# STM32N645 register map
File version: 1.0
CPU: CM55 r0p1, little endian, no MPU, FPU, vendor SysTick, 8 interrupt priority bits
Registers are 32-bit, read-write, reset 0x0 unless marked. A register's access mark holds for its fields unless they carry their own. Offsets are from the block's base; [hi:lo] are bit positions; {n}, {i} and the like mark numbered series.

## DMA2D — Chrom-ART Accelerator controller
Base 0x48021000
Same registers: DMA2D_S 0x58021000
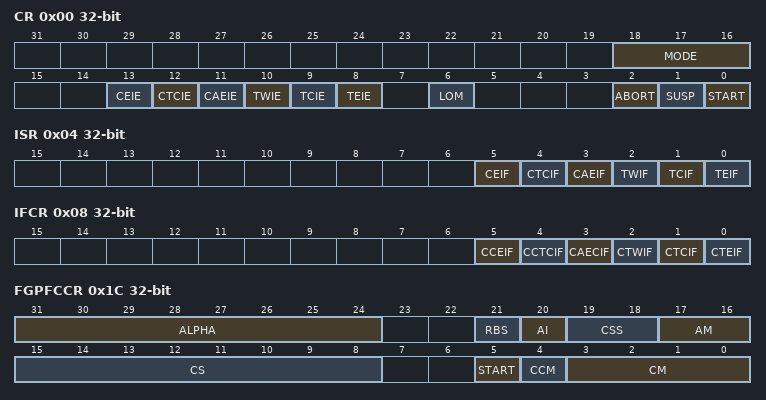
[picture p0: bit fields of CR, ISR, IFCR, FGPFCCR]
0x00 CR — DMA2D control register
  [18:16] MODE — DMA2D mode
  [13] CEIE — Configuration error (CE) interrupt enable
  [12] CTCIE — CLUT transfer complete (CTC) interrupt enable
  [11] CAEIE — CLUT access error (CAE) interrupt enable
  [10] TWIE — Transfer watermark (TW) interrupt enable
  [9] TCIE — Transfer complete (TC) interrupt enable
  [8] TEIE — Transfer error (TE) interrupt enable
  [6] LOM — Line offset mode
  [2] ABORT
  [1] SUSP — Suspend
  [0] START
0x04 ISR ro — DMA2D interrupt status register
  [5] CEIF — Configuration error interrupt flag
  [4] CTCIF — CLUT transfer complete interrupt flag
  [3] CAEIF — CLUT access error interrupt flag
  [2] TWIF — Transfer watermark interrupt flag
  [1] TCIF — Transfer complete interrupt flag
  [0] TEIF — Transfer error interrupt flag
0x08 IFCR — DMA2D interrupt flag clear register
  [5] CCEIF — Clear configuration error interrupt flag
  [4] CCTCIF — Clear CLUT transfer complete interrupt flag
  [3] CAECIF — Clear CLUT access error interrupt flag
  [2] CTWIF — Clear transfer watermark interrupt flag
  [1] CTCIF — Clear transfer complete interrupt flag
  [0] CTEIF — Clear transfer error interrupt flag
0x0C FGMAR — DMA2D foreground memory address register
  [31:0] MA — Memory address, address of the data used for the foreground image
0x10 FGOR — DMA2D foreground offset register
  [15:0] LO — Line offset
0x14 BGMAR — DMA2D background memory address register
  [31:0] MA — Memory address, address of the data used for the background image
0x18 BGOR — DMA2D background offset register
  [15:0] LO — Line offset
0x1C FGPFCCR — DMA2D foreground PFC control register
  [31:24] ALPHA — Alpha value
  [21] RBS — Red/Blue swap
  [20] AI — Alpha inverted
  [19:18] CSS — Chroma subsampling
  [17:16] AM — Alpha mode
  [15:8] CS — CLUT size
  [5] START
  [4] CCM — CLUT color mode
  [3:0] CM — Color mode
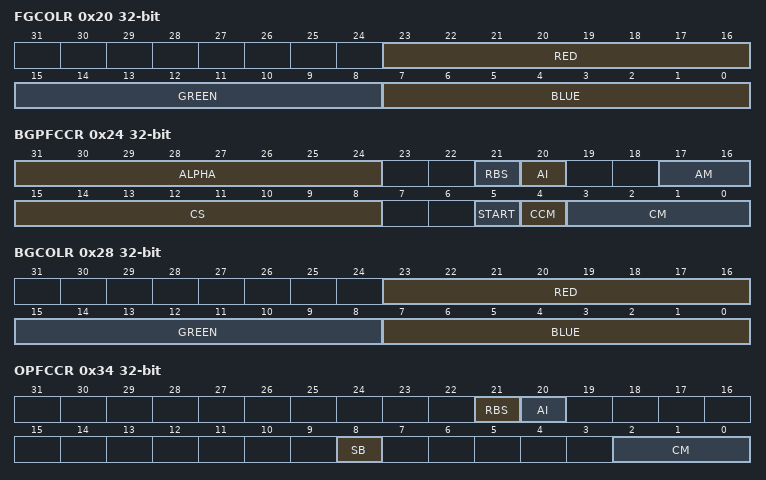
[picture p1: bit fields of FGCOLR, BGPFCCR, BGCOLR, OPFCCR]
0x20 FGCOLR — DMA2D foreground color register
  [23:16] RED — Red value for the A4 or A8 mode of the foreground image
  [15:8] GREEN — Green value for the A4 or A8 mode of the foreground image
  [7:0] BLUE — Blue value for the A4 or A8 mode of the foreground image
0x24 BGPFCCR — DMA2D background PFC control register
  [31:24] ALPHA — Alpha value
  [21] RBS — Red/Blue swap
  [20] AI — Alpha Inverted
  [17:16] AM — Alpha mode
  [15:8] CS — CLUT size
  [5] START
  [4] CCM — CLUT color mode
  [3:0] CM — Color mode
0x28 BGCOLR — DMA2D background color register
  [23:16] RED — Red value for the A4 or A8 mode of the background
  [15:8] GREEN — Green value for the A4 or A8 mode of the background
  [7:0] BLUE — Blue value for the A4 or A8 mode of the background
0x2C FGCMAR — DMA2D foreground CLUT memory address register
  [31:0] MA — Memory address
0x30 BGCMAR — DMA2D background CLUT memory address register
  [31:0] MA — Memory address
0x34 OPFCCR — DMA2D output PFC control register
  [21] RBS — Red/Blue swap
  [20] AI — Alpha Inverted
  [8] SB — Swap bytes
  [2:0] CM — Color mode
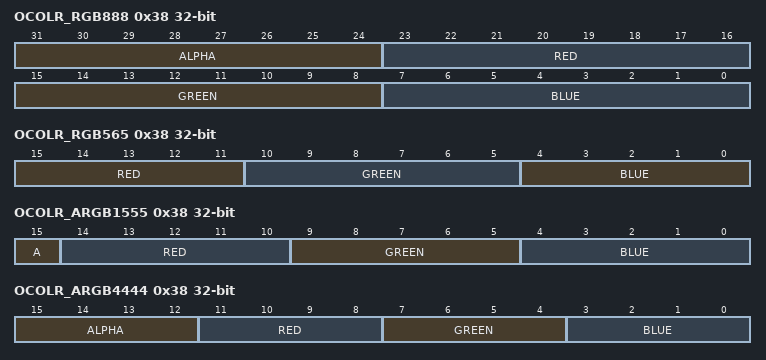
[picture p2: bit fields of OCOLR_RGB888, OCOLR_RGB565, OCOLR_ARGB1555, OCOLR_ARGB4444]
0x38 OCOLR_RGB888 — DMA2D output color register
  [31:24] ALPHA — Alpha channel value of the output color in ARGB8888 mode (otherwise reserved)
  [23:16] RED — Red value of the output image in ARGB8888 or RGB888 mode
  [15:8] GREEN — Green value of the output image in ARGB8888 or RGB888
  [7:0] BLUE — Blue value of the output image in ARGB8888 or RGB888
0x38 OCOLR_RGB565 (alternate view of OCOLR_RGB888) — DMA2D output color register
  [15:11] RED — Red value of the output image in RGB565 mode
  [10:5] GREEN — Green value of the output image in RGB565 mode
  [4:0] BLUE — Blue value of the output image in RGB565 mode
0x38 OCOLR_ARGB1555 (alternate view of OCOLR_RGB888) — DMA2D output color register
  [15] A — Alpha channel value of the output color in ARGB1555 mode
  [14:10] RED — Red value of the output image in ARGB1555 mode
  [9:5] GREEN — Green value of the output image in ARGB1555 mode
  [4:0] BLUE — Blue value of the output image in ARGB1555 mode
0x38 OCOLR_ARGB4444 (alternate view of OCOLR_RGB888) — DMA2D output color register
  [15:12] ALPHA — Alpha channel of the output color value in ARGB4444
  [11:8] RED — Red value of the output image in ARGB4444 mode
  [7:4] GREEN — Green value of the output image in ARGB4444 mode
  [3:0] BLUE — Blue value of the output image in ARGB4444 mode
0x3C OMAR — DMA2D output memory address register
  [31:0] MA — Memory address
0x40 OOR — DMA2D output offset register
  [15:0] LO — Line offset
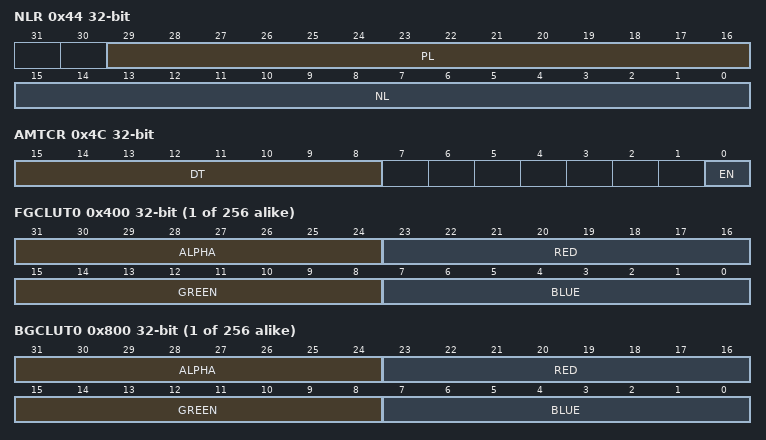
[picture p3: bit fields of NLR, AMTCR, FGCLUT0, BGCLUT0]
0x44 NLR — DMA2D number of line register
  [29:16] PL — Pixel per lines per lines of the area to be transferred
  [15:0] NL — Number of lines of the area to be transferred.
0x48 LWR — DMA2D line watermark register
  [15:0] LW — Line watermark for interrupt generation
0x4C AMTCR — DMA2D AXI master timer configuration register
  [15:8] DT — Dead time
  [0] EN — Dead-time functionality enable
{0x400+4i} FGCLUT{i} reset not defined (i=0..255) — DMA2D foreground CLUT
  [31:24] ALPHA, [23:16] RED, [15:8] GREEN, [7:0] BLUE
{0x800+4i} BGCLUT{i} reset not defined (i=0..255) — DMA2D background CLUT
  [31:24] ALPHA, [23:16] RED, [15:8] GREEN, [7:0] BLUE
